VERSION "Honda Accord B-CAN transmitter grouping"

NS_ :

BS_:

BU_: METER MICU ALT XXX UNKNOWN

BO_ 2398622870 XXX_0x0EF81496: 1 XXX
 SG_ UNKNOWN_1 : 0|8@1+ (1,0) [0|255] ""  UNKNOWN

BO_ 2398647154 ALT_0x0EF87372: 2 ALT
 SG_ UNKNOWN_1 : 0|8@1+ (1,0) [0|255] ""  UNKNOWN
 SG_ AUTO_LIGHT_SENSOR_RAW_REF : 8|8@1+ (1,0) [0|255] ""  UNKNOWN
CM_ SG_ 2398647154 UNKNOWN_1 "Feeds illumination mode and automatic light commands";
CM_ SG_ 2398647154 AUTO_LIGHT_SENSOR_RAW_REF "Raw automatic light sensor reading";

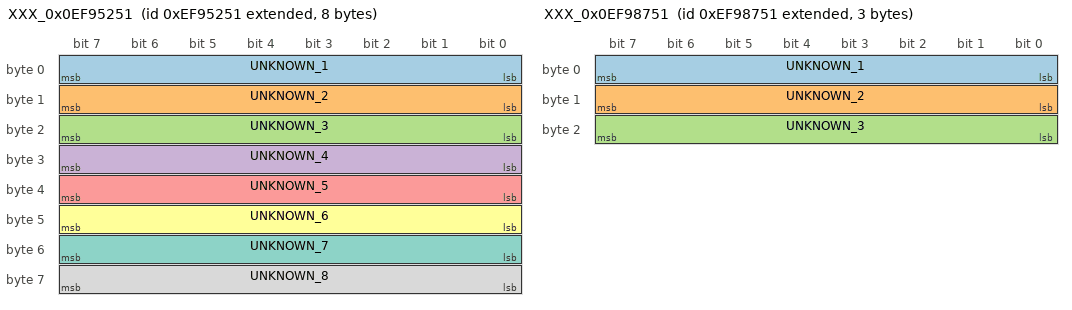
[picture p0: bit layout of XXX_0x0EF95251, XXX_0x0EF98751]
BO_ 2398704209 XXX_0x0EF95251: 8 XXX
 SG_ UNKNOWN_1 : 0|8@1+ (1,0) [0|255] ""  UNKNOWN
 SG_ UNKNOWN_2 : 8|8@1+ (1,0) [0|255] ""  UNKNOWN
 SG_ UNKNOWN_3 : 16|8@1+ (1,0) [0|255] ""  UNKNOWN
 SG_ UNKNOWN_4 : 24|8@1+ (1,0) [0|255] ""  UNKNOWN
 SG_ UNKNOWN_5 : 32|8@1+ (1,0) [0|255] ""  UNKNOWN
 SG_ UNKNOWN_6 : 40|8@1+ (1,0) [0|255] ""  UNKNOWN
 SG_ UNKNOWN_7 : 48|8@1+ (1,0) [0|255] ""  UNKNOWN
 SG_ UNKNOWN_8 : 56|8@1+ (1,0) [0|255] ""  UNKNOWN

BO_ 2398717777 XXX_0x0EF98751: 3 XXX
 SG_ UNKNOWN_1 : 0|8@1+ (1,0) [0|255] ""  UNKNOWN
 SG_ UNKNOWN_2 : 8|8@1+ (1,0) [0|255] ""  UNKNOWN
 SG_ UNKNOWN_3 : 16|8@1+ (1,0) [0|255] ""  UNKNOWN

BO_ 2465735318 XXX_0x12F82296: 1 XXX
 SG_ UNKNOWN_1 : 0|8@1+ (1,0) [0|255] ""  UNKNOWN

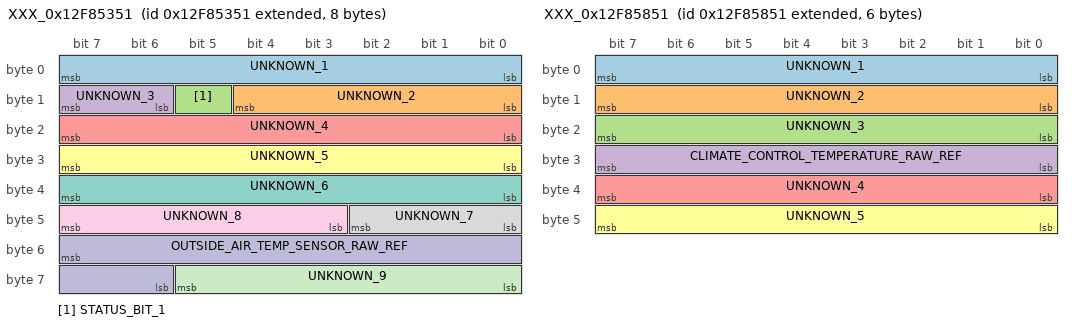
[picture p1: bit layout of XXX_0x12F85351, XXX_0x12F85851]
BO_ 2465747793 XXX_0x12F85351: 8 XXX
 SG_ UNKNOWN_1 : 0|8@1+ (1,0) [0|255] ""  UNKNOWN
 SG_ UNKNOWN_2 : 8|5@1+ (1,0) [0|31] ""  UNKNOWN
 SG_ STATUS_BIT_1 : 13|1@1+ (1,0) [0|1] ""  UNKNOWN
 SG_ UNKNOWN_3 : 14|2@1+ (1,0) [0|3] ""  UNKNOWN
 SG_ UNKNOWN_4 : 16|8@1+ (1,0) [0|255] ""  UNKNOWN
 SG_ UNKNOWN_5 : 24|8@1+ (1,0) [0|255] ""  UNKNOWN
 SG_ UNKNOWN_6 : 32|8@1+ (1,0) [0|255] ""  UNKNOWN
 SG_ UNKNOWN_7 : 40|3@1+ (1,0) [0|7] ""  UNKNOWN
 SG_ UNKNOWN_8 : 43|5@1+ (1,0) [0|31] ""  UNKNOWN
 SG_ OUTSIDE_AIR_TEMP_SENSOR_RAW_REF : 55|10@0+ (1,0) [0|1023] ""  UNKNOWN
 SG_ UNKNOWN_9 : 56|6@1+ (1,0) [0|63] ""  UNKNOWN
CM_ SG_ 2465747793 OUTSIDE_AIR_TEMP_SENSOR_RAW_REF "Sensor uses a nonlinear temperature conversion";
CM_ SG_ 2465747793 UNKNOWN_9 "Feeds LIN 0x2B climate control code";

BO_ 2465749073 XXX_0x12F85851: 6 XXX
 SG_ UNKNOWN_1 : 0|8@1+ (1,0) [0|255] ""  UNKNOWN
 SG_ UNKNOWN_2 : 8|8@1+ (1,0) [0|255] ""  UNKNOWN
 SG_ UNKNOWN_3 : 16|8@1+ (1,0) [0|255] ""  UNKNOWN
 SG_ CLIMATE_CONTROL_TEMPERATURE_RAW_REF : 24|8@1+ (1,0) [0|255] ""  UNKNOWN
 SG_ UNKNOWN_4 : 32|8@1+ (1,0) [0|255] ""  UNKNOWN
 SG_ UNKNOWN_5 : 40|8@1+ (1,0) [0|255] ""  UNKNOWN
CM_ SG_ 2465749073 UNKNOWN_1 "Feeds LIN 0x2B climate control data";
CM_ SG_ 2465749073 CLIMATE_CONTROL_TEMPERATURE_RAW_REF "Feeds F-CAN 0x221 climate control temperature";

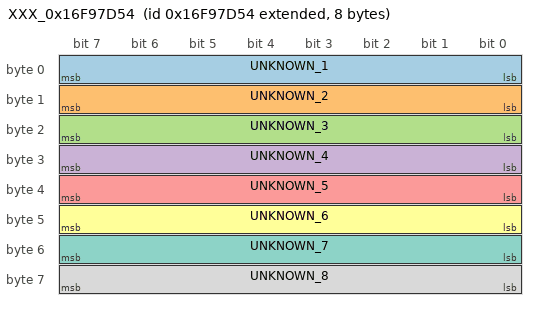
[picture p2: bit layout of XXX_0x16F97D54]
BO_ 2532932948 XXX_0x16F97D54: 8 XXX
 SG_ UNKNOWN_1 : 0|8@1+ (1,0) [0|255] ""  UNKNOWN
 SG_ UNKNOWN_2 : 8|8@1+ (1,0) [0|255] ""  UNKNOWN
 SG_ UNKNOWN_3 : 16|8@1+ (1,0) [0|255] ""  UNKNOWN
 SG_ UNKNOWN_4 : 24|8@1+ (1,0) [0|255] ""  UNKNOWN
 SG_ UNKNOWN_5 : 32|8@1+ (1,0) [0|255] ""  UNKNOWN
 SG_ UNKNOWN_6 : 40|8@1+ (1,0) [0|255] ""  UNKNOWN
 SG_ UNKNOWN_7 : 48|8@1+ (1,0) [0|255] ""  UNKNOWN
 SG_ UNKNOWN_8 : 56|8@1+ (1,0) [0|255] ""  UNKNOWN
